# ATA5835 device description
Architecture: AVR8; Family: megaAVR
Registers are 8-bit, access not given, no defined reset value unless marked. A register's access mark holds for its fields unless they carry their own. Offsets are from the block's base; [hi:lo] are bit positions; {n}, {i} and the like mark numbered series.

## DFIFO
Instances: DFIFO 0x00
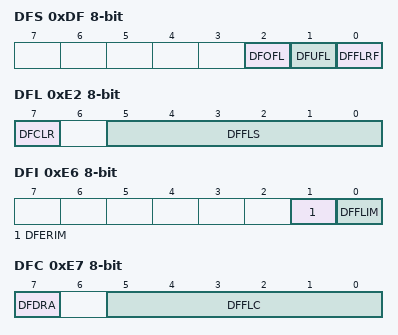
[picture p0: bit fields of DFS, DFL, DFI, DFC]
0xDF DFS — Data FIFO Status
  [2] DFOFL — Data FIFO Overflow Flag
  [1] DFUFL — Data FIFO Underflow Flag
  [0] DFFLRF — Data FIFO Fill Level Reached Status Flag
0xE0 DFTL 16-bit bits used 11:0 — Data FIFO Telegram Length
0xE2 DFL — Data FIFO Fill Level
  [7] DFCLR — Data FIFO Clear
  [5:0] DFFLS — Data FIFO Fill Level Status
0xE3 DFWP bits used 4:0 — Data FIFO Write Pointer
0xE4 DFRP bits used 5:0 — Data FIFO Read Pointer
0xE5 DFD — Data FIFO Data
0xE6 DFI — Data FIFO Interrupt Mask
  [1] DFERIM — Data FIFO Error Interrupt Mask
  [0] DFFLIM — Data FIFO Fill Level Interrupt Mask
0xE7 DFC — Data FIFO Configuration
  [7] DFDRA — Data FIFO Direct Read Access Operational Mode
  [5:0] DFFLC — Data FIFO Fill Level Configuration

## EEPROM
Instances: EEPROM 0x00
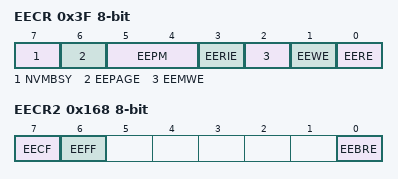
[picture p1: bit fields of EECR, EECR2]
0x3F EECR — EEPROM Control Register
  [7] NVMBSY — Non-Volatile Memory Busy
  [6] EEPAGE — EEPROM Page Access
  [5:4] EEPM — EEPROM Programming Mode
    0=Erase and Write in one operation; 1=Erase Only; 2=Write Only
  [3] EERIE — EEPROM Ready Interrupt Enable
  [2] EEMWE — EEPROM Master Write Enable
  [1] EEWE — EEPROM Write Enable
  [0] EERE — EEPROM Read Enable
0x40 EEDR — EEPROM Data Register
0x41 EEAR 16-bit bits used 10:0 — EEPROM Address Register
0x43 EEPR — EEPROM Protect Register
  [3:0] EEAP — EEPROM Access Protect
0x168 EECR2 — EEPROM Control Register 2
  [7] EECF — EEPROM Error Correction Flag
  [6] EEFF — EEPROM Error Fault Flag
  [0] EEBRE — EEPROM Burst Read Enable
0x169 PGMST — Program Memory Status Register
  [4:0] PGMSYN — Program Memory Syndrome
0x16A EEST — EEPROM Status Register
  [3:0] EESYN — EEPROM Syndrome

## FE
Instances: FE 0x00
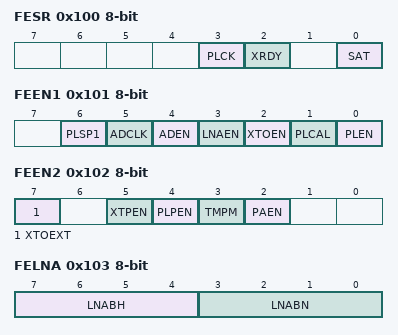
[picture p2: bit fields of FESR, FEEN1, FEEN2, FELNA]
0x100 FESR — RF Front End Status Register
  [3] PLCK — PLL Locked
  [2] XRDY — XTO Ready
  [0] SAT — LNA Saturated
0x101 FEEN1 — RF Front End Enable 1
  [6] PLSP1 — PLL Speedup 1
  [5] ADCLK — ADC Clock Enable
  [4] ADEN — Analog Digital Converter Enable
  [3] LNAEN — Low Noise Amplifier Enable
  [2] XTOEN — Crystal Oscillator Enable
  [1] PLCAL — PLL Calibration Mode
  [0] PLEN — PLL Enable
0x102 FEEN2 — RF Front End Enable 2
  [7] XTOEXT — XTO External Clock
  [5] XTPEN — XTO Voltage Pump Enable
  [4] PLPEN — PLL Post Enable
  [3] TMPM — Temperature Measurement
  [2] PAEN — Power Amplifier Enable
0x103 FELNA — RF Front End LNA Bias
  [7:4] LNABH — LNA Bias High Sense Mode
  [3:0] LNABN — LNA Bias Normal Sense Mode
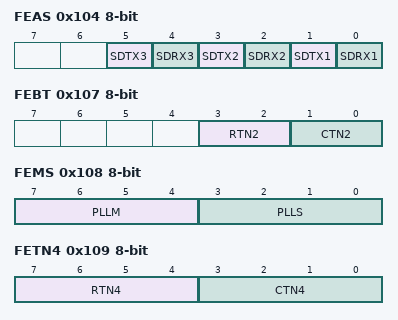
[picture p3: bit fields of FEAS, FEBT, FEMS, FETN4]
0x104 FEAS — RF Front End Antenna Switch
  [5] SDTX3 — SPDT RF Switch Tx 3
  [4] SDRX3 — SPDT RF Switch Rx 3
  [3] SDTX2 — SPDT RF Switch Tx 2
  [2] SDRX2 — SPDT RF Switch Rx 2
  [1] SDTX1 — SPDT RF Switch Tx 1
  [0] SDRX1 — SPDT RF Switch Rx 1
0x105 FEPAC — RF Front End Power Amplifier Control
  [7:0] FEPAC
    0=-11.80 -12.90; 1=-11.30 -12.33; 2=-10.70 -11.76; 3=-10.20 -11.10; 4=-9.70 -10.60; 5=-9.20 -10.00; 6=-8.60 -9.50; 7=-8.00 -9.00; 8=-7.50 -8.50; 9=-7.00 -7.90; 10=-6.40 -7.30; 11=-5.90 -6.80; 12=-5.30 -6.30; 13=-4.77 -5.70; 14=-4.17 -5.20; 15=-3.67 -4.60; 16=-3.12 -4.07; 17=-2.56 -3.47; 18=-2.10 -2.97; 19=-1.58 -2.42; 20=-1.08 -1.86; 21=-0.50 -1.40; 22=0.00 -0.88; 23=0.41 -0.38; 24=1.00 0.20; 25=1.42 0.70; 26=1.83 1.11; 27=2.42 1.70; 28=2.88 2.12; 29=3.38 2.53; 30=3.81 3.12; 31=4.31 3.58; 32=4.72 4.08; 33=5.09 4.51; 34=5.57 5.01; 35=6.00 5.42; 36=6.41 5.79; 37=6.77 6.27; 38=7.19 6.70; 39=7.55 7.11; 40=7.98 7.47; 41=8.40 7.89; 42=8.79 8.25; 43=9.11 8.68; 44=9.46 9.10; 45=9.82 9.49; 46=10.18 9.81; 47=10.60 10.16; 48=10.89 10.52; 49=11.30 10.88; 50=11.62 11.30; 51=12.06 11.59; 52=12.39 12.00; 53=12.82 12.32; 54=13.22 12.76; 55=13.58 13.09; 56=13.95 13.52; 57=14.22 13.92; 58=14.41 14.28; 59=14.49 14.65; {v}=14.60 14.65 (v=60..63)
0x106 FEVCT bits used 3:0 — RF Front End VCO Tuning
0x107 FEBT — RF Front End RC Tuning
  [3:2] RTN2 — 2 Bit Resistor Tuning
  [1:0] CTN2 — 2 Bit Capacitor Tuning
0x108 FEMS — RF Front End Main and Swallow Counter
  [7:4] PLLM — PLL Main
  [3:0] PLLS — PLL Swallow
0x109 FETN4 — RF Front End RC Tuning 4bit Register
  [7:4] RTN4 — 4 Bit Resistor Tuning
  [3:0] CTN4 — 4 Bit Capacitor Tuning
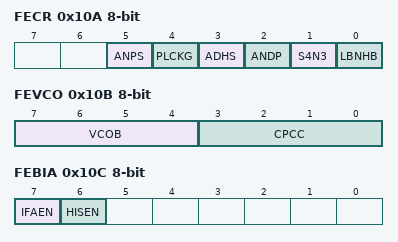
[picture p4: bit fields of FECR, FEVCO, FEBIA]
0x10A FECR — RF Front End Control Register
  [5] ANPS — ASK Not DPSK Switch
  [4] PLCKG — PLL Lock Detect Gate
  [3] ADHS — ADC High Sample Rate
  [2] ANDP — Antenna Damping
  [1] S4N3 — Select 433MHz Not 315MHz Band
  [0] LBNHB — Low-Band Not High-Band
0x10B FEVCO — RF Front End VCO and PLL Control
  [7:4] VCOB — VCO Bias
  [3:0] CPCC — Charge Pump Current Control
0x10C FEBIA — RF Front End Amplifier Bias
  [7] IFAEN — IF Amplifier Enable
  [6] HISEN — High Sensitivity Enable
0x10D SPARE1 — RF Front End Spare Register 1
  [7:0] CHBIR — Calibration of High Band Image Rejection
